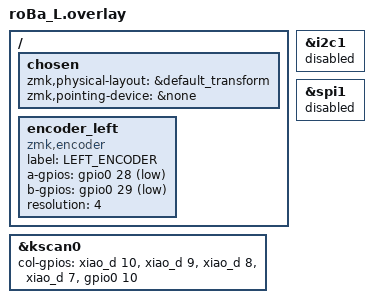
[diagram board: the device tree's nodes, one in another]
#include "roBa.dtsi"

 / {
    /* 左は物理レイアウト明示＋ポインタ無し */
    chosen {
        zmk,physical-layout = &default_transform;
        zmk,pointing-device = &none;
    };

    /* 左エンコーダ（ピンは仮。後で実配線に） */
    encoder_left: encoder_left {
        compatible = "zmk,encoder";
        label = "LEFT_ENCODER";
        a-gpios = <&gpio0 28 GPIO_ACTIVE_LOW>;
        b-gpios = <&gpio0 29 GPIO_ACTIVE_LOW>;
        resolution = <4>;
        status = "okay";
    };
};

/* ★ col-gpios を与える（必須）。ピン番号は後で実配線に合わせてOK */
&kscan0 {
    col-gpios = <&xiao_d 10 GPIO_ACTIVE_HIGH>,
                <&xiao_d 9  GPIO_ACTIVE_HIGH>,
                <&xiao_d 8  GPIO_ACTIVE_HIGH>,
                <&xiao_d 7  GPIO_ACTIVE_HIGH>,
                <&gpio0  10 GPIO_ACTIVE_HIGH>;
};

/* 右のポインタ用バスが左に来ないよう保険 */
&i2c1 { status = "disabled"; };
&spi1 { status = "disabled"; };
